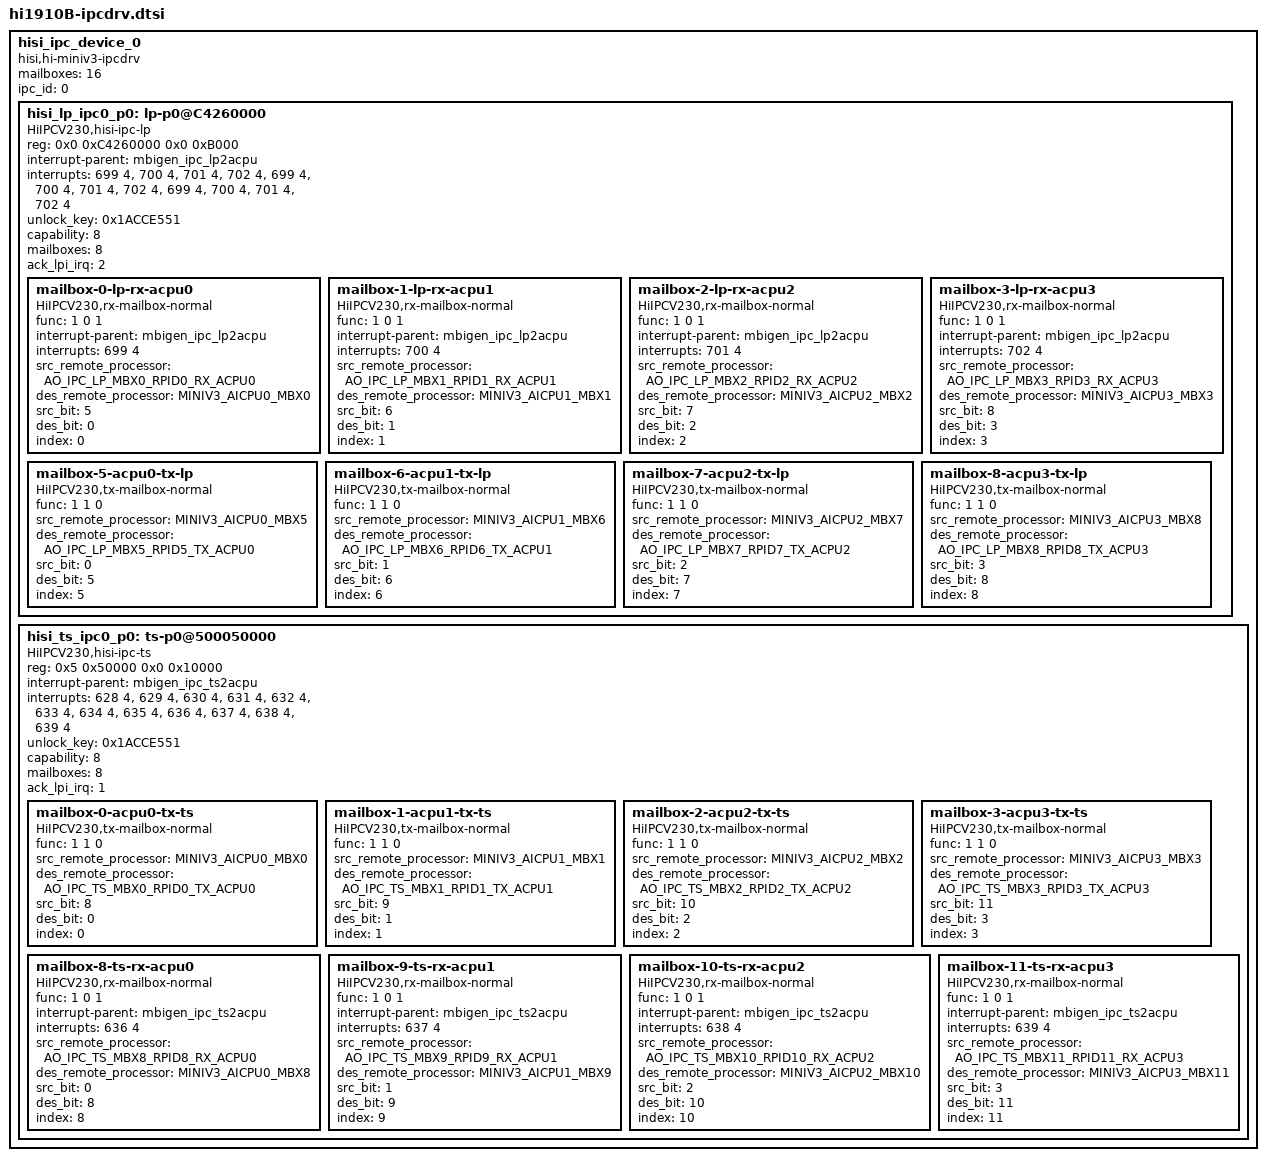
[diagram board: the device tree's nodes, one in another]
/*
 * Hisilicon Ltd. Hi3650 SoC
 *
 * Copyright (C) 2012-2014 Hisilicon Ltd.
 *
 * This program is free software; you can redistribute it and/or modify
 * it under the terms of the GNU General Public License version 2 as
 * publishhed by the Free Software Foundation.
 */

hisi_ipc_device_0 {
	#address-cells = <2>;
	#size-cells = <2>;

	compatible = "hisi,hi-miniv3-ipcdrv";
	mailboxes = <16>;
	ipc_id = <0>;
	ranges;

	/* ipc lp normal unsafe mailbox */
	hisi_lp_ipc0_p0: lp-p0@C4260000 {
		#address-cells = <2>;
		#size-cells = <2>;
		compatible = "HiIPCV230,hisi-ipc-lp";
		reg = <0x0 0xC4260000 0x0 0xB000>;
		interrupt-parent = <&mbigen_ipc_lp2acpu>;
		interrupts = <699 4>, <700 4>, <701 4>, <702 4>, <699 4>, <700 4>, <701 4>, <702 4>, <699 4>, <700 4>, <701 4>, <702 4>;
				     /*ACPU0    ACPU1     ACPU2      ACPU3 */
		unlock_key = <0x1ACCE551>;
		capability = <8>;
		mailboxes = <8>;
		ack_lpi_irq = <2>;

		/*
		 * "func"
		 * <mbox_type, is_src_mbox, is_des_mbox>;
		 */
		/*lp rx normal unsafe mbx channel*/
		mailbox-0-lp-rx-acpu0 {
			compatible = "HiIPCV230,rx-mailbox-normal";
			func = <1 0 1>;
			interrupt-parent = <&mbigen_ipc_lp2acpu>;
			interrupts = <699 4>;
			src_remote_processor = "AO_IPC_LP_MBX0_RPID0_RX_ACPU0";
			des_remote_processor = "MINIV3_AICPU0_MBX0";
			src_bit = <5>;
			des_bit = <0>;
			index = <0>;
		};

		mailbox-1-lp-rx-acpu1 {
			compatible = "HiIPCV230,rx-mailbox-normal";
			func = <1 0 1>;
			interrupt-parent = <&mbigen_ipc_lp2acpu>;
			interrupts = <700 4>;
			src_remote_processor = "AO_IPC_LP_MBX1_RPID1_RX_ACPU1";
			des_remote_processor = "MINIV3_AICPU1_MBX1";
			src_bit = <6>;
			des_bit = <1>;
			index = <1>;
		};

		mailbox-2-lp-rx-acpu2 {
			compatible = "HiIPCV230,rx-mailbox-normal";
			func = <1 0 1>;
			interrupt-parent = <&mbigen_ipc_lp2acpu>;
			interrupts = <701 4>;
			src_remote_processor = "AO_IPC_LP_MBX2_RPID2_RX_ACPU2";
			des_remote_processor = "MINIV3_AICPU2_MBX2";
			src_bit = <7>;
			des_bit = <2>;
			index = <2>;
		};

		mailbox-3-lp-rx-acpu3 {
			compatible = "HiIPCV230,rx-mailbox-normal";
			func = <1 0 1>;
			interrupt-parent = <&mbigen_ipc_lp2acpu>;
			interrupts = <702 4>;
			src_remote_processor = "AO_IPC_LP_MBX3_RPID3_RX_ACPU3";
			des_remote_processor = "MINIV3_AICPU3_MBX3";
			src_bit = <8>;
			des_bit = <3>;
			index = <3>;
		};

		/*lp tx normal unsafe mbx channel*/
		mailbox-5-acpu0-tx-lp {
			compatible = "HiIPCV230,tx-mailbox-normal";
			func = <1 1 0>;
			src_remote_processor = "MINIV3_AICPU0_MBX5";
			des_remote_processor = "AO_IPC_LP_MBX5_RPID5_TX_ACPU0";
			src_bit = <0>;
			des_bit = <5>;
			index = <5>;
		};

		mailbox-6-acpu1-tx-lp {
			compatible = "HiIPCV230,tx-mailbox-normal";
			func = <1 1 0>;
			src_remote_processor = "MINIV3_AICPU1_MBX6";
			des_remote_processor = "AO_IPC_LP_MBX6_RPID6_TX_ACPU1";
			src_bit = <1>;
			des_bit = <6>;
			index = <6>;
		};

		mailbox-7-acpu2-tx-lp {
			compatible = "HiIPCV230,tx-mailbox-normal";
			func = <1 1 0>;
			src_remote_processor = "MINIV3_AICPU2_MBX7";
			des_remote_processor = "AO_IPC_LP_MBX7_RPID7_TX_ACPU2";
			src_bit = <2>;
			des_bit = <7>;
			index = <7>;
		};

		mailbox-8-acpu3-tx-lp {
			compatible = "HiIPCV230,tx-mailbox-normal";
			func = <1 1 0>;
			src_remote_processor = "MINIV3_AICPU3_MBX8";
			des_remote_processor = "AO_IPC_LP_MBX8_RPID8_TX_ACPU3";
			src_bit = <3>;
			des_bit = <8>;
			index = <8>;
		};
	};

	/* ipc ts normal unsafe mailbox */
	hisi_ts_ipc0_p0: ts-p0@500050000 {
		#address-cells = <2>;
		#size-cells = <2>;
		compatible = "HiIPCV230,hisi-ipc-ts";
		reg = <0x5 0x50000 0x0 0x10000>;
		interrupt-parent = <&mbigen_ipc_ts2acpu>;
		interrupts = <628 4>, <629 4>, <630 4>, <631 4>, <632 4>, <633 4>, <634 4>, <635 4>, <636 4>, <637 4>, <638 4>, <639 4>;
		unlock_key = <0x1ACCE551>;
		capability = <8>;
		mailboxes = <8>;
		ack_lpi_irq = <1>;

		/*
		 * "func"
		 * <mbox_type, is_src_mbox, is_des_mbox>;
		 */
		/*ts tx normal unsafe mbx channel*/
		mailbox-0-acpu0-tx-ts {
			compatible = "HiIPCV230,tx-mailbox-normal";
		    func = <1 1 0>;
			src_remote_processor = "MINIV3_AICPU0_MBX0";
			des_remote_processor = "AO_IPC_TS_MBX0_RPID0_TX_ACPU0";
			src_bit = <8>;
			des_bit = <0>;
			index = <0>;
		};

		mailbox-1-acpu1-tx-ts {
			compatible = "HiIPCV230,tx-mailbox-normal";
			func = <1 1 0>;
			src_remote_processor = "MINIV3_AICPU1_MBX1";
			des_remote_processor = "AO_IPC_TS_MBX1_RPID1_TX_ACPU1";
			src_bit = <9>;
			des_bit = <1>;
			index = <1>;
		};

		mailbox-2-acpu2-tx-ts {
			compatible = "HiIPCV230,tx-mailbox-normal";
			func = <1 1 0>;
			src_remote_processor = "MINIV3_AICPU2_MBX2";
			des_remote_processor = "AO_IPC_TS_MBX2_RPID2_TX_ACPU2";
			src_bit = <10>;
			des_bit = <2>;
			index = <2>;
		};

		mailbox-3-acpu3-tx-ts {
			compatible = "HiIPCV230,tx-mailbox-normal";
			func = <1 1 0>;
			src_remote_processor = "MINIV3_AICPU3_MBX3";
			des_remote_processor = "AO_IPC_TS_MBX3_RPID3_TX_ACPU3";
			src_bit = <11>;
			des_bit = <3>;
			index = <3>;
		};

		/*ts rx normal unsafe mbx channel*/
		mailbox-8-ts-rx-acpu0 {
			compatible = "HiIPCV230,rx-mailbox-normal";
			func = <1 0 1>;
		    interrupt-parent = <&mbigen_ipc_ts2acpu>;
			interrupts = <636 4>;
			src_remote_processor = "AO_IPC_TS_MBX8_RPID8_RX_ACPU0";
			des_remote_processor = "MINIV3_AICPU0_MBX8";
			src_bit = <0>;
			des_bit = <8>;
			index = <8>;
		};

		mailbox-9-ts-rx-acpu1 {
			compatible = "HiIPCV230,rx-mailbox-normal";
			func = <1 0 1>;
			interrupt-parent = <&mbigen_ipc_ts2acpu>;
			interrupts = <637 4>;
			src_remote_processor = "AO_IPC_TS_MBX9_RPID9_RX_ACPU1";
			des_remote_processor = "MINIV3_AICPU1_MBX9";
			src_bit = <1>;
			des_bit = <9>;
			index = <9>;
		};

		mailbox-10-ts-rx-acpu2 {
			compatible = "HiIPCV230,rx-mailbox-normal";
			func = <1 0 1>;
			interrupt-parent = <&mbigen_ipc_ts2acpu>;
			interrupts = <638 4>;
			src_remote_processor = "AO_IPC_TS_MBX10_RPID10_RX_ACPU2";
			des_remote_processor = "MINIV3_AICPU2_MBX10";
			src_bit = <2>;
			des_bit = <10>;
			index = <10>;
		};

		mailbox-11-ts-rx-acpu3 {
			compatible = "HiIPCV230,rx-mailbox-normal";
			func = <1 0 1>;
			interrupt-parent = <&mbigen_ipc_ts2acpu>;
			interrupts = <639 4>;
			src_remote_processor = "AO_IPC_TS_MBX11_RPID11_RX_ACPU3";
			des_remote_processor = "MINIV3_AICPU3_MBX11";
			src_bit = <3>;
			des_bit = <11>;
			index = <11>;
		};
	};
};
